AUTOSAR XML (schema 00044)
standard types defined: sint8, uint8
package /AtomicSwComponent
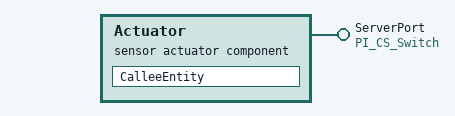
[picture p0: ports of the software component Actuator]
  sensor actuator sw component type Actuator
    provide port ServerPort: server-com-spec{operation=Operation, queue-length=1}, provided-interface=PI_CS_Switch
    behavior Actuator_IB: handle-termination-and-restart=NO-SUPPORT
      operation invoked event OI_CalleeEntity_ServerPort_Operation: start-on-event=CalleeEntity, operation=ServerPort.Operation
      runnable CalleeEntity: can-be-invoked-concurrently=true
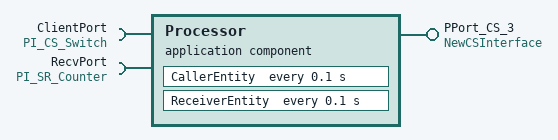
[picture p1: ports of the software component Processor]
  application sw component type Processor
    require port ClientPort: client-com-spec=Operation, required-interface=PI_CS_Switch
    require port RecvPort: nonqueued-receiver-com-spec{data-element=DataElement, init-value=0}, required-interface=PI_SR_Counter
    provide port PPort_CS_3: provided-interface=NewCSInterface
    behavior Processor_IB: handle-termination-and-restart=NO-SUPPORT
      timing event T_100ms_CallerEntity: start-on-event=CallerEntity, period=0.1
      timing event T_100ms_ReceiverEntity: start-on-event=ReceiverEntity, period=0.1
      explicit-inter-runnable-variables:
        data localData: type=Switch, init-value=0
      runnable CallerEntity
        read-local-variables:
          access RLV_localData: accessed-variable=localData
        sync call SSCP_ClientPort_Operation: operation=ClientPort.Operation, timeout=0.0
      runnable ReceiverEntity
        data-receive-point-by-arguments:
          access DRPA_RecvPort_DataElement: accessed-variable=RecvPort.DataElement
        read-local-variables:
          access WLV_localData: accessed-variable=localData
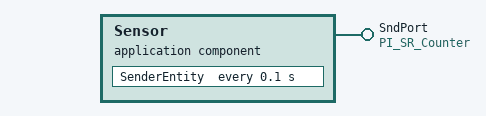
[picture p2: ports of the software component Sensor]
  application sw component type Sensor
    provide port SndPort: nonqueued-sender-com-spec{data-element=DataElement, init-value=0}, provided-interface=PI_SR_Counter
    behavior Sensor_IB: handle-termination-and-restart=NO-SUPPORT
      timing event T_100ms_SenderEntity: start-on-event=SenderEntity, period=0.1
      runnable SenderEntity
        data-send-points:
          access DSP_SndPort_DataElement: accessed-variable=SndPort.DataElement
  application sw component type NewSWC_1
    require port RPort_CS_1: required-interface=NewCSInterface
    behavior NewSWC_1_IB: handle-termination-and-restart=NO-SUPPORT
package /CompositionSwComponent
  composition sw component type Ecu
    component Actuator: type=Actuator
    component Processor: type=Processor
    component Sensor: type=Sensor
    connect Actuator.ServerPort -> Processor.ClientPort
    connect Sensor.SndPort -> Processor.RecvPort
package /DataType/ApplicationDataType
  app type Counter: category=VALUE, range raw 0..9
  app type Switch: category=VALUE, range raw 0..1
package /DataType/ImplementationDataType
  impl type Counter: category=VALUE, base-type=uint8
  impl type Switch: category=VALUE, base-type=sint8
package /DataType/Mapping
  data type mapping set DataTypeMappingSet
    data-type-maps:
      application-data-type=Counter, implementation-data-type=Counter
      application-data-type=Switch, implementation-data-type=Switch
package /ECU
  ecu instance Ecu: sleep-mode-supported=false, wake-up-over-bus-supported=false
package /PortInterface
  client server interface PI_CS_Switch
    operation Operation
      arg Argument: type=Switch, direction=IN
  sender receiver interface PI_SR_Counter
    data DataElement: type=Counter
package /SYSTEM
  system System: category=ECU_EXTRACT, system-version=1.0.0
    system mapping SystemMapping
      sw-mappings:
        swc to ecu mapping SwcToEcuMapping: component=[RootSwComposition.Actuator, RootSwComposition.Processor, RootSwComposition.Sensor], ecu-instance=Ecu
    root-software-compositions:
      root sw composition prototype RootSwComposition: software-composition=Ecu
